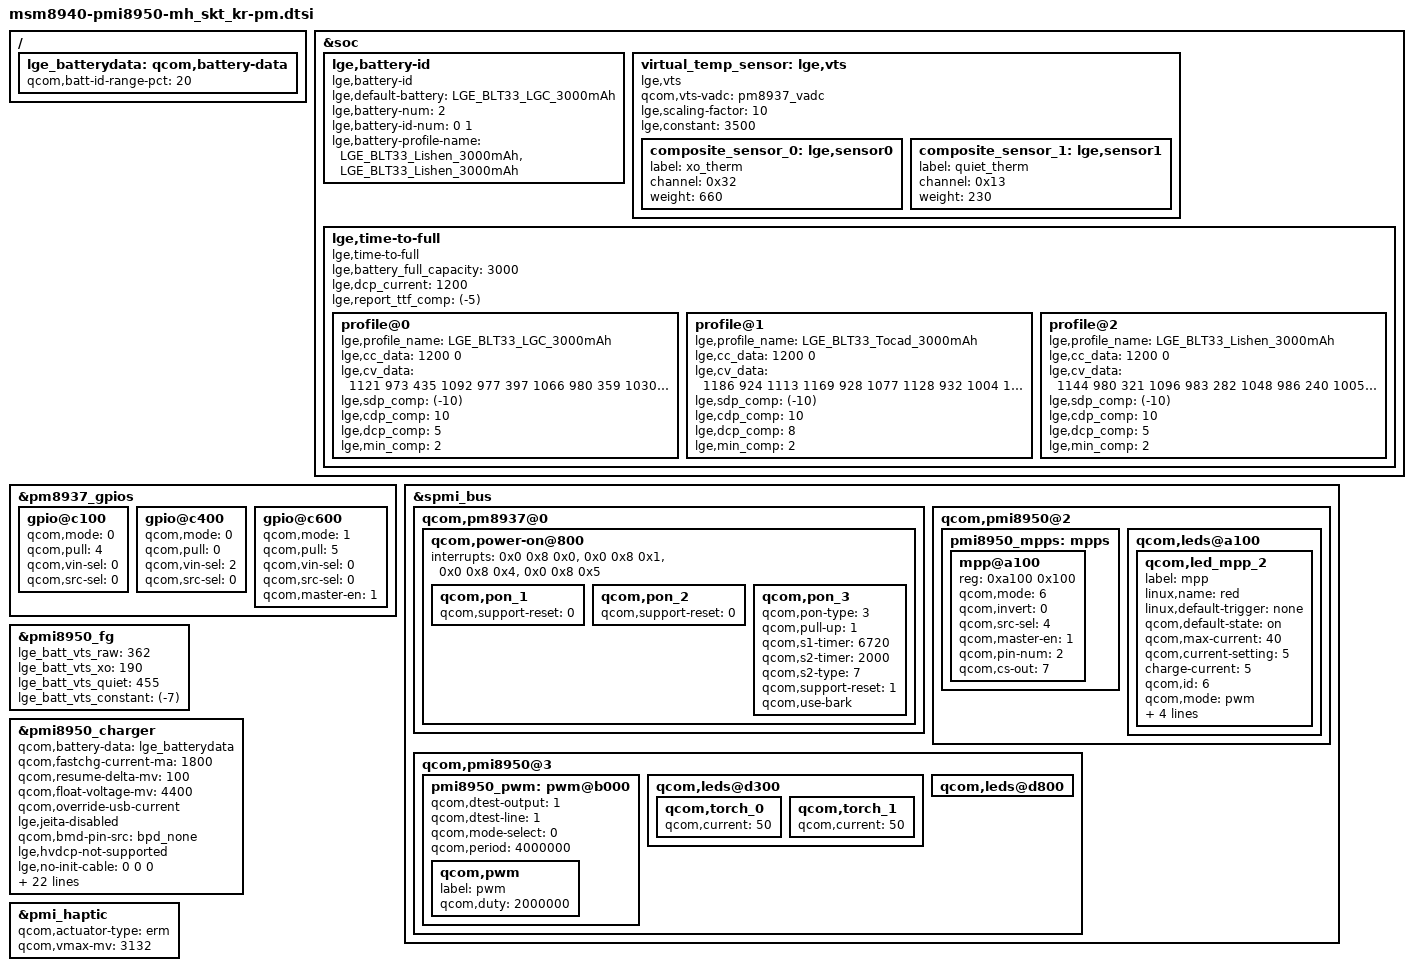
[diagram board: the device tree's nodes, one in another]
/*
 * Copyright (c) 2016, The Linux Foundation. All rights reserved.
 *
 * This program is free software; you can redistribute it and/or modify
 * it under the terms of the GNU General Public License version 2 and
 * only version 2 as published by the Free Software Foundation.
 *
 * This program is distributed in the hope that it will be useful,
 * but WITHOUT ANY WARRANTY; without even the implied warranty of
 * MERCHANTABILITY or FITNESS FOR A PARTICULAR PURPOSE.  See the
 * GNU General Public License for more details.
 */

/{
	lge_batterydata: qcom,battery-data {
		qcom,batt-id-range-pct = <20>;
		#include "../battery_profile/LGE_BLT33_LGC_3000mAh.dtsi"
		#include "../battery_profile/LGE_BLT33_Tocad_3000mAh.dtsi"
		#include "../battery_profile/LGE_BLT33_Lishen_3000mAh.dtsi"
	};
};

&soc {
	lge,battery-id{
		compatible = "lge,battery-id";
		/delete-property/ lge,restrict-mode-enabled;
		/*default battery profile*/
		lge,default-battery = "LGE_BLT33_LGC_3000mAh";
		/*Total number of combined of battery cell and battery id */
		lge,battery-num = <2>;
		/* battery id and battery profile match numbers */
		lge,battery-id-num = <0 1>;
		/* battery profile */
		lge,battery-profile-name = "LGE_BLT33_Lishen_3000mAh",
						"LGE_BLT33_Lishen_3000mAh";
	};

	/* vts = (0.66*xo_therm) + (0.23*quiet_therm) + (3.5) */
	virtual_temp_sensor: lge,vts {
		compatible = "lge,vts";
		qcom,vts-vadc = <&pm8937_vadc>;
		lge,scaling-factor= <10>;
		lge,constant = <3500>;
		composite_sensor_0: lge,sensor0 {
			label = "xo_therm";
			channel = <0x32>;
			weight = <660>;
		};
		composite_sensor_1: lge,sensor1 {
			label = "quiet_therm";
			channel = <0x13>;
			weight = <230>;
		};
	};

	/* time to full */
	lge,time-to-full {
		compatible = "lge,time-to-full";
		lge,battery_full_capacity = <3000>;
		lge,dcp_current = <1200>;
		lge,report_ttf_comp = <(-5)>;
		profile@0 {
			lge,profile_name = "LGE_BLT33_LGC_3000mAh";
				    /* current  soc */
			lge,cc_data = < 1200	0>;
				    /* current  soc    time */
			lge,cv_data = < 1121	973	435
					1092	977	397
					1066	980	359
					1030	983	316
					986	986	270
					941	989	222
					883	992	171
					831	995	117
					788	998	60
					739	1000	0>;
			lge,sdp_comp = <(-10)>;
			lge,cdp_comp = <10>;
			lge,dcp_comp = <5>;
			lge,min_comp = <2>;
		};
		profile@1 {
			lge,profile_name = "LGE_BLT33_Tocad_3000mAh";
				    /* current  soc */
			lge,cc_data = < 1200	0>;
				    /* current  soc    time */
			lge,cv_data = < 1186	924	1113
					1169	928	1077
					1128	932	1004
					1120	937	957
					1109	941	911
					1074	945	866
					1046	949	824
					1011	954	783
					976	958	739
					942	962	695
					914	966	649
					879	970	602
					844	973	552
					814	977	501
					783	980	447
					750	983	392
					716	986	334
					688	989	274
					657	992	210
					622	995	144
					590	998	74
					563	1000	0>;
			lge,sdp_comp = <(-10)>;
			lge,cdp_comp = <10>;
			lge,dcp_comp = <8>;
			lge,min_comp = <2>;
		};
		profile@2 {
			lge,profile_name = "LGE_BLT33_Lishen_3000mAh";
				    /* current  soc */
			lge,cc_data = < 1200	0>;
				    /* current  soc    time */
			lge,cv_data = < 1144	980	321
					1096	983	282
					1048	986	240
					1005	989	197
					959	992	151
					911	995	103
					867	998	53
					820	1000	0>;
			lge,sdp_comp = <(-10)>;
			lge,cdp_comp = <10>;
			lge,dcp_comp = <5>;
			lge,min_comp = <2>;
		};
	};
};

&pm8937_gpios {
	gpio@c100 {
		qcom,mode = <0>;
		qcom,pull = <4>;
		qcom,vin-sel = <0>;
		qcom,src-sel = <0>;
		status = "okay";
	};
	gpio@c400 {
		qcom,mode = <0>;
		qcom,pull = <0>;
		qcom,vin-sel = <2>;
		qcom,src-sel = <0>;
		status = "okay";
	};
	gpio@c600 {
		status = "okay";
		qcom,mode = <1>;
		qcom,pull = <5>;
		qcom,vin-sel = <0>;
		qcom,src-sel = <0>;
		qcom,master-en = <1>;
	};
};

&spmi_bus {
	qcom,pm8937@0 {
		qcom,power-on@800 {
			interrupts = <0x0 0x8 0x0>,
				     <0x0 0x8 0x1>,
				     <0x0 0x8 0x4>,
				     <0x0 0x8 0x5>;
			interrupt-names = "kpdpwr", "resin",
				"resin-bark", "kpdpwr-resin-bark";

			qcom,pon_1 {
				status = "ok";
				qcom,support-reset = <0>;
			};
			qcom,pon_2 {
				status = "ok";
				qcom,support-reset = <0>;
			};
			qcom,pon_3 {
				status = "ok";
				qcom,pon-type = <3>;
				qcom,pull-up = <1>;
				qcom,s1-timer = <6720>;
				qcom,s2-timer = <2000>;
				qcom,s2-type = <7>;
				qcom,support-reset = <1>;
				qcom,use-bark;
			};
		};
	};

	qcom,pmi8950@2 {
		pmi8950_mpps: mpps {
			mpp@a100 {
				status = "okay";
				reg = <0xa100 0x100>;
				qcom,mode = <6>;
				qcom,invert = <0>;
				qcom,src-sel = <4>;
				qcom,master-en = <1>;
				qcom,pin-num = <2>;
				qcom,cs-out = <7>;
			};
		};
		qcom,leds@a100 {
			status = "okay";
			qcom,led_mpp_2 {
				label = "mpp";
				linux,name = "red";
				linux,default-trigger = "none";
				qcom,default-state = "on";
				qcom,max-current = <40>;
				qcom,current-setting = <5>;
				charge-current = <5>;
				qcom,id = <6>;
				qcom,mode = "pwm";
				qcom,pwm-us = <1000>;
				qcom,source-sel = <8>;
				qcom,mode-ctrl = <0x60>;
				pwms = <&pmi8950_pwm 0 0>;
			};
		};
	};

	qcom,pmi8950@3 {
		pmi8950_pwm: pwm@b000 {
			status = "ok";
			qcom,dtest-output = <1>;
			qcom,dtest-line = <1>;
			qcom,mode-select = <0>;
			qcom,period = <4000000>;
			qcom,pwm {
				label = "pwm";
				qcom,duty = <2000000>;
			};
		};
		qcom,leds@d300 {
			qcom,torch_0 {
				qcom,current = <50>;
			};
			qcom,torch_1 {
				qcom,current = <50>;
			};
		};
		qcom,leds@d800 {
			/delete-property/ qcom,en-ext-pfet-sc-pro;
		};
	};
};

&pmi8950_fg {
	lge_batt_vts_raw = <362>;
	lge_batt_vts_xo = <190>;
	lge_batt_vts_quiet = <455>;
	lge_batt_vts_constant = <(-7)>;
};

&pmi8950_charger {
	qcom,battery-data = <&lge_batterydata>;
	qcom,fastchg-current-ma = <1800>;
	qcom,resume-delta-mv = <100>;
	qcom,float-voltage-mv = <4400>;
	qcom,override-usb-current;
	lge,jeita-disabled;
	qcom,bmd-pin-src = "bpd_none";
	lge,hvdcp-not-supported;

	/* ref resistance 200K */
	lge,no-init-cable = <0 0 0>;
	lge,cable-mhl-1k = <5000 500 500>;
	lge,cable-u-28p7k = <10000 1800 500>;
	lge,cable-28p7k = <250000 1800 500>;
	lge,cable-56k = <600000 1500 1500>;
	lge,cable-100k = <620000 1800 500>;
	lge,cable-130k = <780000 1500 1500>;
	lge,cable-180k = <870000 1800 500>;
	lge,cable-200k = <910000 1800 500>;
	lge,cable-220k = <960000 1800 500>;
	lge,cable-270k = <1050000 1800 500>;
	lge,cable-330k = <1150000 1800 500>;
	lge,cable-620k = <1380000 1800 500>;
	lge,cable-910k = <1630000 1500 1500>;
	lge,cable-none = <1900000 1800  500>;

	lge,usb-max-current-ma = <1800>;
	lge,iusb = <1800 1000>;
	lge,ibat = <1800 1000>;
	lge,otp-warm-ibat = <900>;
	lge,otp-cold-ibat = <900>;
	lge,battery-spec-size = <4>;
		lge,battery-spec = <
			0 10 4400 600	/* 0.2C */
			10 20 4400 900	/* 0.3C */
			20 45 4400 1800	/* 0.6C */
			45 60 4400 900	/* 0.3C */
		>;
};

&pmi_haptic {
        status = "okay";
        qcom,actuator-type = "erm";
        qcom,vmax-mv = <3132>;
};
